AUTOSAR XML (schema 00049)
package /Components
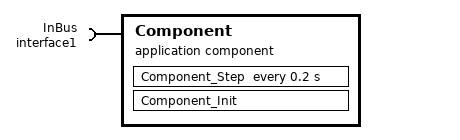
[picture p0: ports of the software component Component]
  application sw component type Component
    require port InBus: nonqueued-receiver-com-spec{data-element=a, init-value=Enum1_enum1}, required-interface=interface1
    behavior Component_IB: data-type-mapping=myDataTypeMappingSet, handle-termination-and-restart=NO-SUPPORT
      timing event Event_Component_Step: start-on-event=Component_Step, period=0.2
      runnable Component_Init
      runnable Component_Step
